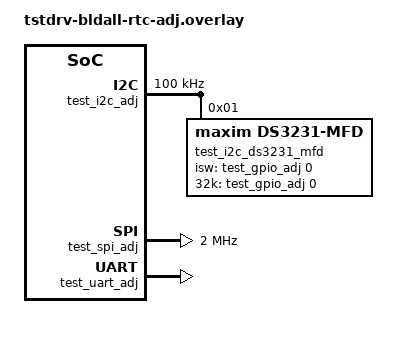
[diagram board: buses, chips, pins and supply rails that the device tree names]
/*
 * Copyright (c) 2024 TiaC Systems
 *
 * SPDX-License-Identifier: Apache-2.0
 *
 * Snipped overlay for testing driver builds
 *
 * Names in this file should be chosen in a way that won't conflict
 * with real-world devicetree nodes, to allow these tests to run on
 * (and be extended to test) real hardware.
 */

/ {
	test: test {
		#address-cells = <1>;
		#size-cells = <1>;
	};
};

&test {
	test_gpio_adj: gpio@feedface {
		compatible = "vnd,gpio";
		status = "okay";
		reg = <0xfeedface 0x1000>;
		gpio-controller;
		#gpio-cells = <0x2>;
	};

	test_i2c_adj: i2c@aaaabbbb {
		compatible = "vnd,i2c";
		status = "okay";
		reg = <0xaaaabbbb 0x1000>;
		#address-cells = <1>;
		#size-cells = <0>;
		clock-frequency = <100000>;

		test_i2c_ds3231_mfd: ds3231-mfd@1 {
			compatible = "maxim,ds3231-mfd";
			status = "okay";
			reg = <0x1>;
			isw-gpios = <&test_gpio_adj 0 0>;
			32k-gpios = <&test_gpio_adj 0 0>;

			test_i2c_ds3231_rtc: ds3231-rtc {
				compatible = "maxim,ds3231-rtc";
				status = "okay";
			};
		};
	};

	test_spi_adj: spi@ccccdddd {
		compatible = "vnd,spi";
		status = "okay";
		reg = <0xccccdddd 0x1000>;
		#address-cells = <1>;
		#size-cells = <0>;
		clock-frequency = <2000000>;

		/* one entry for every devices */
		/* cs-gpios = <&test_gpio_adj 0 0>; */
	};

	test_uart_adj: uart@eeeeffff {
		compatible = "vnd,serial";
		status = "okay";
		reg = <0xeeeeffff 0x1000>;
	};
};
